# WKUP_CTRL_MMR_WKUP_CTRL_MMR_CFG0_43000000h register map
Vendor: Texas Instruments
Registers are 32-bit, read-write, reset 0x0 unless marked. A register's access mark holds for its fields unless they carry their own. Offsets are as the file gives them; [hi:lo] are bit positions; {n}, {i} and the like mark numbered series.

## WKUP_CTRL_MMR_CFG0 (part 2 of 3)
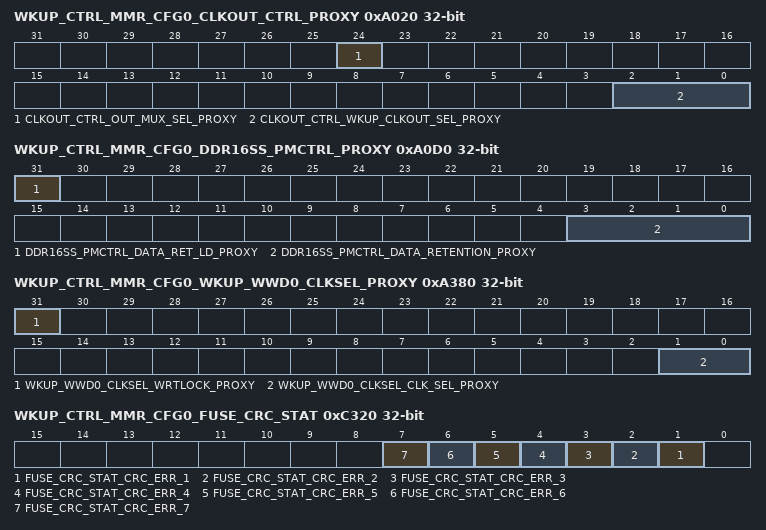
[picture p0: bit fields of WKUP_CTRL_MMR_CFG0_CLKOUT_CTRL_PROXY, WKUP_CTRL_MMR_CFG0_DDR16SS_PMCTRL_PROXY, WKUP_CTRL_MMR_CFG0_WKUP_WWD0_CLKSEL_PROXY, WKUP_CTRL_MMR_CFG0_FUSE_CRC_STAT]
0xA020 WKUP_CTRL_MMR_CFG0_CLKOUT_CTRL_PROXY
  [24] CLKOUT_CTRL_OUT_MUX_SEL_PROXY — WKUP CLKOUT (Pin) pin output mux selection. HFOSC0_CLK is a direct output from the HFOSC0 Reset Source: mod_por_rst_n
  [2:0] CLKOUT_CTRL_WKUP_CLKOUT_SEL_PROXY — Controls WKUP CLKOUT MUX for WKUP_CLKOUT0 PinField values (others are reserved):undefined - undefined3'b000 - DRIVE_LOWundefined - undefined3'b001 - LFOSC0_CLKOUT3'b010 - MAIN_PLL0_HSDIV2_CLKOUT3'b011 - MAIN_PLL1_HSDIV2_CLKOUT3'b100 - MAIN_PLL2_HSDIV9_CLKOUT3'b101 - DEVICE_CLKOUT_32K3'b110 - CLK_12M_RC3'b111 - HFOSC0_CLKOUT Reset Source: mod_por_rst_n
0xA030 WKUP_CTRL_MMR_CFG0_WKUP_GTC_CLKSEL_PROXY reset 0x1
  [2:0] WKUP_GTC_CLKSEL_CLK_SEL_PROXY — Selects the GTC timebase clock sourceField values (others are reserved):3'b000 - MAIN_PLL2_HSDIV5_CLKOUT3'b001 - MAIN_PLL0_HSDIV6_CLKOUT3'b010 - CPSW2G_CPTS_RFT_CLK3'b011 - Reserved '0'3'b100 - MCU_EXT_REFCLK03'b101 - EXT_REFCLK13'b110 - MCU_SYSCLK0undefined - undefined3'b111 - MAIN_SYSCLK0 Reset Source: mod_g_rst_n
0xA03C WKUP_CTRL_MMR_CFG0_EFUSE_CLKSEL_PROXY
  [0] EFUSE_CLKSEL_CLK_SEL_PROXY — Selects the clock sourceField values (others are reserved):1'b0 - HFOSC0_CLKOUT1'b1 - MAIN_SYSCLK0/16 Reset Source: mod_por_rst_n
0xA0D0 WKUP_CTRL_MMR_CFG0_DDR16SS_PMCTRL_PROXY
  [31] DDR16SS_PMCTRL_DATA_RET_LD_PROXY — Controls latching of the retention valueField values (others are reserved):1'b0 - Latch Closed1'b1 - Latch Open Reset Source: mcu_chip1_rst_n
  [3:0] DDR16SS_PMCTRL_DATA_RETENTION_PROXY — DDR16SS Retention: This is a fault tolerant bit field 0x06 Asserts DDRSS 'data_retention' which will Hi-Z most of the phy output pins except for CKE/RESET# All others (Default 0) : data_retention is deasserted for normal DDR16SS OperationField values (others are reserved):4'b0110 - Retention Activated4'b0000 - Retention Deactivated Reset Source: mcu_chip1_rst_n
0xA190 WKUP_CTRL_MMR_CFG0_USB0_CLKSEL_PROXY
  [0] USB0_CLKSEL_REFCLK_SEL_PROXY — Selects the clock source for the USB0 ref_clk. Field values (others are reserved):1'b0 - HFOSC0_CLKOUT1'b1 - MAIN_PLL0_HSDIV8_CLKOUT Reset Source: mod_g_rst_n
0xA194 WKUP_CTRL_MMR_CFG0_USB1_CLKSEL_PROXY
  [0] USB1_CLKSEL_REFCLK_SEL_PROXY — Selects the clock source for the USB1 ref_clk. Field values (others are reserved):1'b0 - HFOSC0_CLKOUT1'b1 - MAIN_PLL0_HSDIV8_CLKOUT Reset Source: mod_g_rst_n
0xA1B0 WKUP_CTRL_MMR_CFG0_WKUP_TIMER0_CLKSEL_PROXY
  [2:0] WKUP_TIMER0_CLKSEL_CLK_SEL_PROXY — Timer functional clock input select mux controlField values (others are reserved):3'b000 - HFOSC0_CLKOUT3'b001 - DM_CLK/2undefined - undefined3'b010 - CLK_12M_RC3'b011 - MCU_PLL0_HSDIV3_CLKOUT3'b100 - MCU_EXT_REFCLK0 (pin)3'b101 - DEVICE_CLKOUT_32K3'b110 - CPSW2G_CPTS_RFT_CLK3'b111 - CLK_32K_RC Reset Source: sys_por_rst_n
0xA1B4 WKUP_CTRL_MMR_CFG0_WKUP_TIMER1_CLKSEL_PROXY
  [2:0] WKUP_TIMER1_CLKSEL_CLK_SEL_PROXY — Timer functional clock input select mux controlField values (others are reserved):3'b000 - HFOSC0_CLKOUT3'b001 - DM_CLK/2undefined - undefined3'b010 - CLK_12M_RC3'b011 - MCU_PLL0_HSDIV3_CLKOUT3'b100 - MCU_EXT_REFCLK0 (pin)3'b101 - DEVICE_CLKOUT_32K3'b110 - CPSW2G_CPTS_RFT_CLK3'b111 - CLK_32K_RC Reset Source: sys_por_rst_n
0xA340 WKUP_CTRL_MMR_CFG0_WKUP_WWD0_CTRL_PROXY
  [3:0] WKUP_WWD0_CTRL_WWD_STOP_PROXY — Controls Clocks to the WWD Watchdog CounterField values (others are reserved):4'b0000 - WWD Counter Running4'b1010 - WWD Counter Stopped Reset Source: mod_g_rst_n
0xA380 WKUP_CTRL_MMR_CFG0_WKUP_WWD0_CLKSEL_PROXY
  [31] WKUP_WWD0_CLKSEL_WRTLOCK_PROXY — When set, locks WWD0_CLKSEL from further writes until the next module reset. Reset Source: mod_g_rst_n
  [1:0] WKUP_WWD0_CLKSEL_CLK_SEL_PROXY — Windowed watchdog timer functional clock input select mux controlField values (others are reserved):2'b00 - HFOSC0_CLKOUT2'b01 - DEVICE_CLKOUT_32K2'b10 - CLK_12M_RC2'b11 - CLK_32K Reset Source: mod_g_rst_n
0xA600 WKUP_CTRL_MMR_CFG0_WKUP_RTC_CLKSEL_PROXY
  [0] WKUP_RTC_CLKSEL_CLK_SEL_PROXY — Selects the source of the RTC functional clockField values (others are reserved):1'b0 - DEVICE_CLKOUT_32K1'b1 - CLK_32K_RC Reset Source: mod_por_rst_n
{0xB100+4i} WKUP_CTRL_MMR_CFG0_CLAIMREG_P2_R{i} (i=0..12)
  [31:0] CLAIMREG_P2_R{i} — Claim bits for Partition 2 Reset Source: mod_g_rst_n
0xC320 WKUP_CTRL_MMR_CFG0_FUSE_CRC_STAT ro
  [n] FUSE_CRC_STAT_CRC_ERR_{n} (n=1..7) — Indicates eFuse CRC error on chain {n} Reset Source: mod_por_rst_n
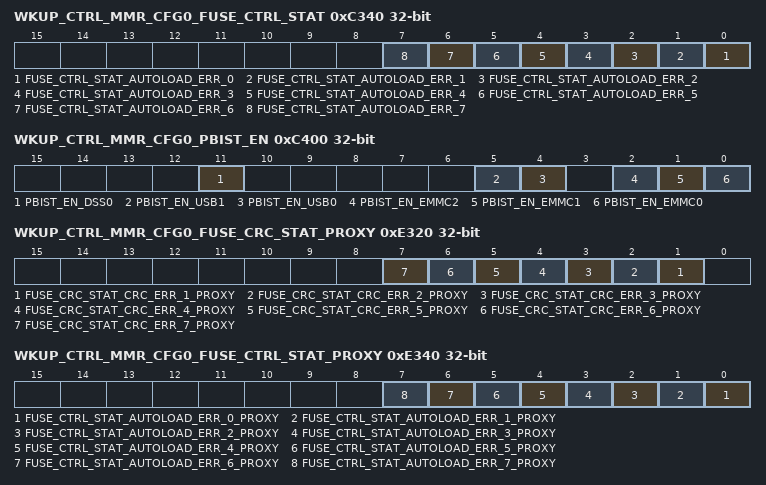
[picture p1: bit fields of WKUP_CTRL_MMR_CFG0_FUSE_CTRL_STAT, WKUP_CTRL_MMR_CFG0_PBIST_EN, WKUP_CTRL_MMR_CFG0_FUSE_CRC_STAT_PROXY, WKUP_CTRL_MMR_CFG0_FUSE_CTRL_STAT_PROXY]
0xC340 WKUP_CTRL_MMR_CFG0_FUSE_CTRL_STAT ro
  [n] FUSE_CTRL_STAT_AUTOLOAD_ERR_{n} (n=0..7) — Autoload Error Status Chain {n} Reset Source: mod_por_rst_n
0xC400 WKUP_CTRL_MMR_CFG0_PBIST_EN
  [11] PBIST_EN_DSS0 — Activates PBIST Access to DSS0 Memories Reset Source: mod_g_rst_n
  [5] PBIST_EN_USB1 — Activates PBIST Access to USB1 Memories Reset Source: mod_g_rst_n
  [4] PBIST_EN_USB0 — Activates PBIST Access to USB0 Memories Reset Source: mod_g_rst_n
  [2] PBIST_EN_EMMC2 — Activates PBIST Access to MMC2 Memories Reset Source: mod_g_rst_n
  [1] PBIST_EN_EMMC1 — Activates PBIST Access to MMC1 Memories Reset Source: mod_g_rst_n
  [0] PBIST_EN_EMMC0 — Activates PBIST Access to MMC0 Memories Reset Source: mod_g_rst_n
{0xD100+4i} WKUP_CTRL_MMR_CFG0_CLAIMREG_P3_R{i}_READONLY ro (i=0..8)
  [31:0] CLAIMREG_P3_R{i}_READONLY — Claim bits for Partition 3 Reset Source: mod_g_rst_n
0xE320 WKUP_CTRL_MMR_CFG0_FUSE_CRC_STAT_PROXY ro
  [n] FUSE_CRC_STAT_CRC_ERR_{n}_PROXY (n=1..7) — Indicates eFuse CRC error on chain {n} Reset Source: mod_por_rst_n
0xE340 WKUP_CTRL_MMR_CFG0_FUSE_CTRL_STAT_PROXY ro
  [n] FUSE_CTRL_STAT_AUTOLOAD_ERR_{n}_PROXY (n=0..7) — Autoload Error Status Chain {n} Reset Source: mod_por_rst_n
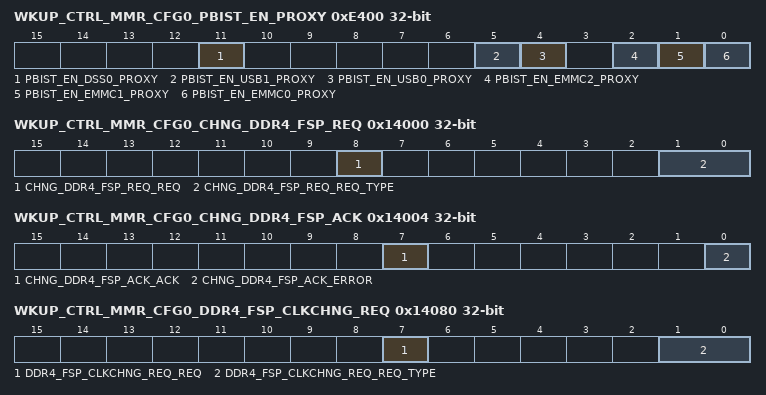
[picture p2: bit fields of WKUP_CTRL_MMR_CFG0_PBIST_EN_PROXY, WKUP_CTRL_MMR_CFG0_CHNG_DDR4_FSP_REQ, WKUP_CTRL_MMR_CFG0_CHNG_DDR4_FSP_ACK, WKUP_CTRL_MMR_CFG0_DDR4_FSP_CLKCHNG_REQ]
0xE400 WKUP_CTRL_MMR_CFG0_PBIST_EN_PROXY
  [11] PBIST_EN_DSS0_PROXY — Activates PBIST Access to DSS0 Memories Reset Source: mod_g_rst_n
  [5] PBIST_EN_USB1_PROXY — Activates PBIST Access to USB1 Memories Reset Source: mod_g_rst_n
  [4] PBIST_EN_USB0_PROXY — Activates PBIST Access to USB0 Memories Reset Source: mod_g_rst_n
  [2] PBIST_EN_EMMC2_PROXY — Activates PBIST Access to MMC2 Memories Reset Source: mod_g_rst_n
  [1] PBIST_EN_EMMC1_PROXY — Activates PBIST Access to MMC1 Memories Reset Source: mod_g_rst_n
  [0] PBIST_EN_EMMC0_PROXY — Activates PBIST Access to MMC0 Memories Reset Source: mod_g_rst_n
{0xF100+4i} WKUP_CTRL_MMR_CFG0_CLAIMREG_P3_R{i} (i=0..8)
  [31:0] CLAIMREG_P3_R{i} — Claim bits for Partition 3 Reset Source: mod_g_rst_n
{0x11100+4i} WKUP_CTRL_MMR_CFG0_CLAIMREG_P4_R{i}_READONLY ro (i=0..8)
  [31:0] CLAIMREG_P4_R{i}_READONLY — Claim bits for Partition 4 Reset Source: mod_g_rst_n
{0x13100+4i} WKUP_CTRL_MMR_CFG0_CLAIMREG_P4_R{i} (i=0..8)
  [31:0] CLAIMREG_P4_R{i} — Claim bits for Partition 4 Reset Source: mod_g_rst_n
0x14000 WKUP_CTRL_MMR_CFG0_CHNG_DDR4_FSP_REQ
  [8] CHNG_DDR4_FSP_REQ_REQ — Initiate FSP frequency change Reset Source: mod_por_rst_n
  [1:0] CHNG_DDR4_FSP_REQ_REQ_TYPE — Frequency request typeIndicates which DDR4 frequency set point to change to Reset Source: mod_por_rst_n
0x14004 WKUP_CTRL_MMR_CFG0_CHNG_DDR4_FSP_ACK ro
  [7] CHNG_DDR4_FSP_ACK_ACK — Frequency change acknowledge.This bit is only valid when CHNG_DDR4_FSP_REQ_req = 1Indication from the DDR Controller that the FSP change operation is complete 0 - FSP change operation in progress 1 - FSP change operation complete Reset Source: mod_por_rst_n
  [0] CHNG_DDR4_FSP_ACK_ERROR — Frequency change errorThis bit is only valid when CHNG_DDR4_FSP_REQ_req = 1 0 - FSP change was sucessful 1 - FSP change was not sucessful Reset Source: mod_por_rst_n
0x14080 WKUP_CTRL_MMR_CFG0_DDR4_FSP_CLKCHNG_REQ ro
  [7] DDR4_FSP_CLKCHNG_REQ_REQ — DDR Controller FSP clock change requestIndicates that the DDR controller needs the DDR clock changed to the frequency indicated by the req_type field. This bit is cleared when the DDR4_FSP_CLKCHNG_ACK_ack bit is set. Reset Source: mod_por_rst_n
  [1:0] DDR4_FSP_CLKCHNG_REQ_REQ_TYPE — Frequency request typeIndicates which DDR4 FSP frequency to which the DDR Controller wants the DDR clock set Reset Source: mod_por_rst_n
0x140C0 WKUP_CTRL_MMR_CFG0_DDR4_FSP_CLKCHNG_ACK
  [0] DDR4_FSP_CLKCHNG_ACK_ACK — DDR FSP clock change ackowledgeThis bit should be set once the DDR clock has been sucessfully changed to the value requested by DDR4_FSP_CLKCHNG_REQ_req_type. Setting this bit will clear the DDR4_FSP_CLKCHNG_REQ_req bit and the associated change request interrupt. Reset Source: mod_por_rst_n
0x15100 WKUP_CTRL_MMR_CFG0_CLAIMREG_P5_R0_READONLY ro
  [31:0] CLAIMREG_P5_R0_READONLY — Claim bits for Partition 5 Reset Source: mod_g_rst_n
0x15104 WKUP_CTRL_MMR_CFG0_CLAIMREG_P5_R1_READONLY ro
  [31:0] CLAIMREG_P5_R1_READONLY — Claim bits for Partition 5 Reset Source: mod_g_rst_n
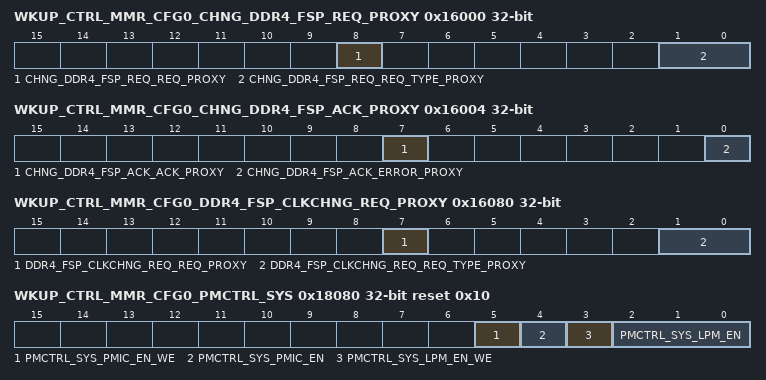
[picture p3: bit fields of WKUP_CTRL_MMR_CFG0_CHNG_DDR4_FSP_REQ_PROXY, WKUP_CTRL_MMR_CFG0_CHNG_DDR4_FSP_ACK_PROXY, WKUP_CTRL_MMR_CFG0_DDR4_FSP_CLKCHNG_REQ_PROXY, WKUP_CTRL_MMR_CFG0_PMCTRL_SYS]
0x16000 WKUP_CTRL_MMR_CFG0_CHNG_DDR4_FSP_REQ_PROXY
  [8] CHNG_DDR4_FSP_REQ_REQ_PROXY — Initiate FSP frequency change Reset Source: mod_por_rst_n
  [1:0] CHNG_DDR4_FSP_REQ_REQ_TYPE_PROXY — Frequency request typeIndicates which DDR4 frequency set point to change to Reset Source: mod_por_rst_n
0x16004 WKUP_CTRL_MMR_CFG0_CHNG_DDR4_FSP_ACK_PROXY ro
  [7] CHNG_DDR4_FSP_ACK_ACK_PROXY — Frequency change acknowledge.This bit is only valid when CHNG_DDR4_FSP_REQ_req = 1Indication from the DDR Controller that the FSP change operation is complete 0 - FSP change operation in progress 1 - FSP change operation complete Reset Source: mod_por_rst_n
  [0] CHNG_DDR4_FSP_ACK_ERROR_PROXY — Frequency change errorThis bit is only valid when CHNG_DDR4_FSP_REQ_req = 1 0 - FSP change was sucessful 1 - FSP change was not sucessful Reset Source: mod_por_rst_n
0x16080 WKUP_CTRL_MMR_CFG0_DDR4_FSP_CLKCHNG_REQ_PROXY ro
  [7] DDR4_FSP_CLKCHNG_REQ_REQ_PROXY — DDR Controller FSP clock change requestIndicates that the DDR controller needs the DDR clock changed to the frequency indicated by the req_type field. This bit is cleared when the DDR4_FSP_CLKCHNG_ACK_ack bit is set. Reset Source: mod_por_rst_n
  [1:0] DDR4_FSP_CLKCHNG_REQ_REQ_TYPE_PROXY — Frequency request typeIndicates which DDR4 FSP frequency to which the DDR Controller wants the DDR clock set Reset Source: mod_por_rst_n
0x160C0 WKUP_CTRL_MMR_CFG0_DDR4_FSP_CLKCHNG_ACK_PROXY
  [0] DDR4_FSP_CLKCHNG_ACK_ACK_PROXY — DDR FSP clock change ackowledgeThis bit should be set once the DDR clock has been sucessfully changed to the value requested by DDR4_FSP_CLKCHNG_REQ_req_type. Setting this bit will clear the DDR4_FSP_CLKCHNG_REQ_req bit and the associated change request interrupt. Reset Source: mod_por_rst_n
0x17100 WKUP_CTRL_MMR_CFG0_CLAIMREG_P5_R0
  [31:0] CLAIMREG_P5_R0 — Claim bits for Partition 5 Reset Source: mod_g_rst_n
0x17104 WKUP_CTRL_MMR_CFG0_CLAIMREG_P5_R1
  [31:0] CLAIMREG_P5_R1 — Claim bits for Partition 5 Reset Source: mod_g_rst_n
0x18040 WKUP_CTRL_MMR_CFG0_FW_CTRL_OUT0
  [31:0] FW_CTRL_OUT0_FW_CTRL_OUT0 — Reset Source: mod_g_rst_n
0x18044 WKUP_CTRL_MMR_CFG0_FW_CTRL_OUT0_SET access not given
  [31:0] FW_CTRL_OUT0_SET_FW_CTRL_OUT0 — reserved Reset Source: mod_g_rst_n (access R/W1TS)
0x18048 WKUP_CTRL_MMR_CFG0_FW_CTRL_OUT0_CLR access not given
  [31:0] FW_CTRL_OUT0_CLR_FW_CTRL_OUT0 — reserved Reset Source: mod_g_rst_n (access R/W1TC)
0x1804C WKUP_CTRL_MMR_CFG0_FW_STS_IN0 ro
  [31:0] FW_STS_IN0_EVENT — Reserved Reset Source: mod_g_rst_n
0x18050 WKUP_CTRL_MMR_CFG0_FW_CTRL_OUT1
  [31:0] FW_CTRL_OUT1_FW_CTRL_OUT1 — reserved Reset Source: mod_g_rst_n
0x18054 WKUP_CTRL_MMR_CFG0_FW_CTRL_OUT1_SET access not given
  [31:0] FW_CTRL_OUT1_SET_FW_CTRL_OUT1 — reserved Reset Source: mod_g_rst_n (access R/W1TS)
0x18058 WKUP_CTRL_MMR_CFG0_FW_CTRL_OUT1_CLR access not given
  [31:0] FW_CTRL_OUT1_CLR_FW_CTRL_OUT1 — reserved Reset Source: mod_g_rst_n (access R/W1TC)
0x1805C WKUP_CTRL_MMR_CFG0_FW_STS_IN1 ro
  [31:0] FW_STS_IN1_EVENT — Reserved Reset Source: mod_g_rst_n
0x18080 WKUP_CTRL_MMR_CFG0_PMCTRL_SYS reset 0x10
  [5] PMCTRL_SYS_PMIC_EN_WE — Unused Field - Value is Don't Care Reset Source: mod_g_rst_n
  [4] PMCTRL_SYS_PMIC_EN — Controls state of PMIC_LPM_EN_OUT when LPM_EN[2:0] is 000 Reset Source: mod_g_rst_n
  [3] PMCTRL_SYS_LPM_EN_WE — Unused Field - Value is Don't Care Reset Source: mod_g_rst_n
  [2:0] PMCTRL_SYS_LPM_EN — Controls whether PMIC_LPM_EN_OUT is driven by the pmic_en bit, or by deep sleep logic. Field values (others are reserved):3'b000 - PMIC_LPM_EN_OUT controlled by pmic_en bit.3'b101 - PMIC_LPM_EN_OUT controlled by DeepSleep Logic Reset Source: mod_g_rst_n
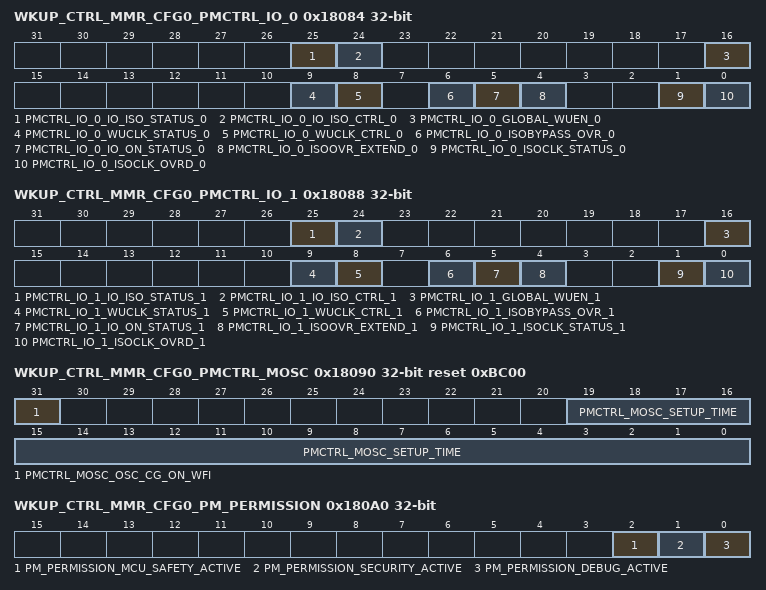
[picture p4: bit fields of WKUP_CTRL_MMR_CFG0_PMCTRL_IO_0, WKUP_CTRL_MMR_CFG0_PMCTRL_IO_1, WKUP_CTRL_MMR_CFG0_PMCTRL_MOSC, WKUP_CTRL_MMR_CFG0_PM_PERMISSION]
0x18084 WKUP_CTRL_MMR_CFG0_PMCTRL_IO_0 access per field
  [25] PMCTRL_IO_0_IO_ISO_STATUS_0 ro — IO ISO Status. Read 0: IO isolation not active. Read 1: IO isolation active.Reflects value of DM input port io_isoack coming back fromIO pad ring. Reset Source: mod_g_rst_n
  [24] PMCTRL_IO_0_IO_ISO_CTRL_0 rw — IO ISO control. Writing this bit to 1 will kick off IO isolation. Reset Source: mod_g_rst_n
  [16] PMCTRL_IO_0_GLOBAL_WUEN_0 rw — Global IO wakeup activate. This is a gating condition to allindividual IO WUEN coming from control module. Gating isdone in the Spinner logic. 0:All individual IO WUEN are gatedin the Spinner logic (override to 0). 1: All individual IO WUENfrom control module are going to Ios.Map to DM input port io_globalwkupen Reset Source: mod_g_rst_n
  [9] PMCTRL_IO_0_WUCLK_STATUS_0 ro — Reflects value of DM input port io_wuclkack coming backfrom IO pad ring. Reset Source: mod_g_rst_n
  [8] PMCTRL_IO_0_WUCLK_CTRL_0 rw — Direct control on WUCLKIN signal to IO pad ring.0:WUCLKINsignal is driven to 0.IO wakeup daisy chain is functional as wellas IO whose wakeup feature is activated. 1:WUCLKIN signal is driven to 1. IO wakeup daisy chain is reset and is latching current pad states and WUEN inputs. Reset Source: mod_g_rst_n
  [6] PMCTRL_IO_0_ISOBYPASS_OVR_0 rw — This MMR bit drives directly DM output port io_isobypassundefined. Reset Source: mod_g_rst_n
  [5] PMCTRL_IO_0_IO_ON_STATUS_0 ro — Gives the functional status of the IO ring. Read 0: Part or all ofthe Ios are not in the ON state that is are in isolation state.Read 1: All Ios are in the ON state.io_on_status = assign 1 if (io_iso == 0 & io_isoack==0 &io_iso_clk == 0 & io_isoclk_ack = 0 ) else 0; Reset Source: mod_g_rst_n
  [4] PMCTRL_IO_0_ISOOVR_EXTEND_0 rw — This drives the SOC chain ISO-OVERRIDE global control.This bit drives directly the DM output port io_isoovrundefined. Atthe SOC level it is used to activate when 1 or gate-off when 0,the individual ISOOR for each IO. This operates as a globalactivate/deactivate for the individual IOs.Control for IO isolation extension.'0' IO isolation is not extended. Transition happens as soon asautomatic restore is completed.'1' IO isolation is extended. The IOs whose ISOOVR bits havebeen individually set in their PADCFG MMRs will all get its IOisolation extended beyond the point when the initial IO daisychain isolation is released. Reset Source: mod_g_rst_n
  [1] PMCTRL_IO_0_ISOCLK_STATUS_0 ro — Reflects value of DM input port io_isoclkack coming backfrom IO pad ring. Reset Source: mod_g_rst_n
  [0] PMCTRL_IO_0_ISOCLK_OVRD_0 rw — Override control on ISOCLKIN signal to IO pad ring.When not overridden this signal is controlled by hardware only.0 ISOCLKIN signal is not override.1 ISOCLKIN signal is overridden to active value ('1'). Reset Source: mod_g_rst_n
0x18088 WKUP_CTRL_MMR_CFG0_PMCTRL_IO_1 access per field
  [25] PMCTRL_IO_1_IO_ISO_STATUS_1 ro — IO ISO Status. Read 0: IO isolation not active. Read 1: IO isolation active.Reflects value of DM input port io_isoack coming back fromIO pad ring. Reset Source: mod_g_rst_n
  [24] PMCTRL_IO_1_IO_ISO_CTRL_1 rw — IO ISO control. Writing this bit to 1 will kick off IO isolation. Reset Source: mod_g_rst_n
  [16] PMCTRL_IO_1_GLOBAL_WUEN_1 rw — Global IO wakeup activate. This is a gating condition to allindividual IO WUEN coming from control module. Gating isdone in the Spinner logic. 0:All individual IO WUEN are gatedin the Spinner logic (override to 0). 1: All individual IO WUENfrom control module are going to Ios.Map to DM input port io_globalwkupen Reset Source: mod_g_rst_n
  [9] PMCTRL_IO_1_WUCLK_STATUS_1 ro — Reflects value of DM input port io_wuclkack coming backfrom IO pad ring. Reset Source: mod_g_rst_n
  [8] PMCTRL_IO_1_WUCLK_CTRL_1 rw — Direct control on WUCLKIN signal to IO pad ring.0:WUCLKINsignal is driven to 0.IO wakeup daisy chain is functional as wellas IO whose wakeup feature is activated. 1:WUCLKIN signal is driven to 1. IO wakeup daisy chain is reset and is latching current pad states and WUEN inputs. Reset Source: mod_g_rst_n
  [6] PMCTRL_IO_1_ISOBYPASS_OVR_1 rw — This MMR bit drives directly DM output port io_isobypassundefined. Reset Source: mod_g_rst_n
  [5] PMCTRL_IO_1_IO_ON_STATUS_1 ro — Gives the functional status of the IO ring. Read 0: Part or all ofthe Ios are not in the ON state that is are in isolation state.Read 1: All Ios are in the ON state.io_on_status = assign 1 if (io_iso == 0 & io_isoack==0 &io_iso_clk == 0 & io_isoclk_ack = 0 ) else 0; Reset Source: mod_g_rst_n
  [4] PMCTRL_IO_1_ISOOVR_EXTEND_1 rw — This drives the SOC chain ISO-OVERRIDE global control.This bit drives directly the DM output port io_isoovrundefined. Atthe SOC level it is used to activate when 1 or gate-off when 0,the individual ISOOR for each IO. This operates as a globalactivate/deactivate for the individual IOs.Control for IO isolation extension.'0' IO isolation is not extended. Transition happens as soon asautomatic restore is completed.'1' IO isolation is extended. The IOs whose ISOOVR bits havebeen individually set in their PADCFG MMRs will all get its IOisolation extended beyond the point when the initial IO daisychain isolation is released. Reset Source: mod_g_rst_n
  [1] PMCTRL_IO_1_ISOCLK_STATUS_1 ro — Reflects value of DM input port io_isoclkack coming backfrom IO pad ring. Reset Source: mod_g_rst_n
  [0] PMCTRL_IO_1_ISOCLK_OVRD_1 rw — Override control on ISOCLKIN signal to IO pad ring.When not overridden this signal is controlled by hardware only.0 ISOCLKIN signal is not override.1 ISOCLKIN signal is overridden to active value ('1'). Reset Source: mod_g_rst_n
0x18090 WKUP_CTRL_MMR_CFG0_PMCTRL_MOSC reset 0xBC00
  [31] PMCTRL_MOSC_OSC_CG_ON_WFI — When set by Device Manager - the soc clock gating logic will gate the device manager clock once Device Manager has entered the WFI state. (Note: this was named osc_cg_dis but name didn't match function) Reset Source: mod_g_rst_n
  [19:0] PMCTRL_MOSC_SETUP_TIME — Keep the main oscillator clock gates for the number ofHFOSC clock cycles This is the time it takes to stabilizethe clock source supplier (i.e. Main Oscillator) Reset Source: mod_g_rst_n
0x18098 WKUP_CTRL_MMR_CFG0_PM_MISC_STATUS ro
  [1:0] PM_MISC_STATUS_OSC_CG_STAT — Reflects the status of the request to clock-gate HFoscillator via MMR PMCTRL_MOSCundefined.11: osc_cgen_req = '0' &osc_cgen_ack = '1'10: osc_cgen_req = '1' &osc_cgen_ack = '0'01: osc_cgen_req = '0' &osc_cgen_ack = '0'00: osc_cgen_req = '1' &osc_cgen_ack = '1' Reset Source: mod_g_rst_n
0x1809C WKUP_CTRL_MMR_CFG0_PMCTRL_IO_GLB
  [1:0] PMCTRL_IO_GLB_DSEN_QUALIFIED — To dsen_qualified signal generation logic for daisychain[1:0] logic. Used to control I/O buffer ouput and output activate during deepsleep mode. See IO Integration spec for detail. Reset Source: mod_g_rst_n
0x180A0 WKUP_CTRL_MMR_CFG0_PM_PERMISSION ro
  [2] PM_PERMISSION_MCU_SAFETY_ACTIVE — Read Only - Reads return a 1 when am62_mcu_ctrl_mmr.wkup_0.RST_MAGIC_WORD_mcu_magic_word_ipcfg[31:0] != 32'h0.When 1, indicates that the MCU is blocking reset and also deep sleep entry. Reset Source: mod_g_rst_n
  [1] PM_PERMISSION_SECURITY_ACTIVE — Read Only - Reads return the value of ms.main_0.sms_iopm_pmpermission_security_active. When 1, indicates that SMS is blocking deep sleep entry. Reset Source: mod_g_rst_n
  [0] PM_PERMISSION_DEBUG_ACTIVE — Read Only - Returns a 1 when IceMelter is blocking deep sleep entry. Reset Source: mod_g_rst_n
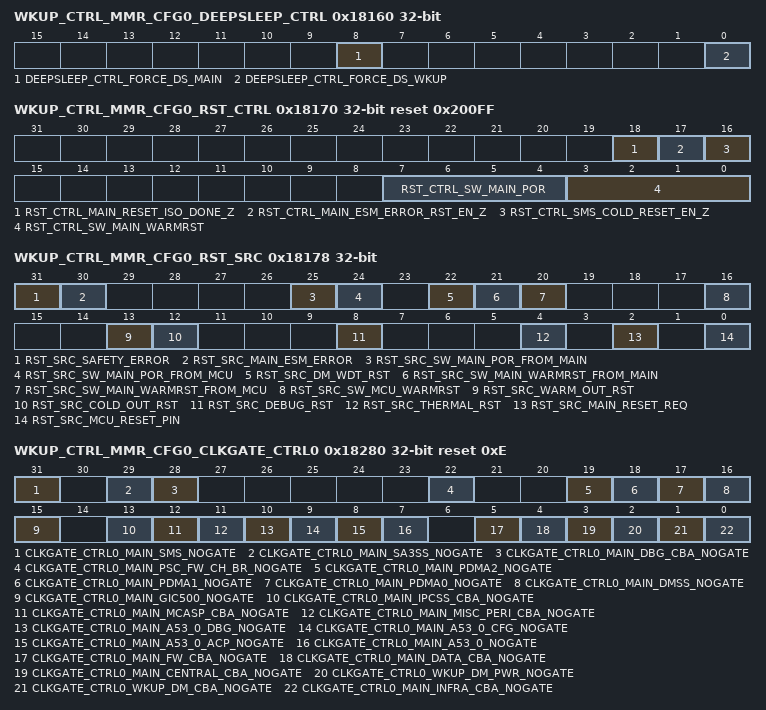
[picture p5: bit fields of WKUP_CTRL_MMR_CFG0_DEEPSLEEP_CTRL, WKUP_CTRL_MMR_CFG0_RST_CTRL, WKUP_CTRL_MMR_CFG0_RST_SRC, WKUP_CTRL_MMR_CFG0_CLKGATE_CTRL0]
0x18160 WKUP_CTRL_MMR_CFG0_DEEPSLEEP_CTRL
  [8] DEEPSLEEP_CTRL_FORCE_DS_MAIN — Force all MAIN IOs into deepsleep mode when set Reset Source: mod_por_rst_n
  [0] DEEPSLEEP_CTRL_FORCE_DS_WKUP — Force all WKUP IOs into deepsleep mode when set Reset Source: mod_por_rst_n
0x18170 WKUP_CTRL_MMR_CFG0_RST_CTRL reset 0x200FF
  [18] RST_CTRL_MAIN_RESET_ISO_DONE_Z — Main Domain CPUs can set this bit to block warm reset in the main domain which is useful when the Main domain may be accessing main domain resources (peripherals, memory..). In this case, the main domain cpus will be notified via an interrupt that there is an outstanding warm reset request for the main domain. Once notified, Main needs to finish any outstanding operations in has with main domain resources and then clear this bit. After this bit is cleared, the main domain warm reset will unblocked and the warm reset sequence may continue. 0 - Reset of Main Domain is not Blocked by Main Domain 1 - Reset of Main Domain is Blocked by Main Domain Reset Source: main_chip1_rst_n
  [17] RST_CTRL_MAIN_ESM_ERROR_RST_EN_Z — Deactivate Reset of Main by ESM 0 - Activated 1 - Deactivated Reset Source: main_chip1_rst_n
  [16] RST_CTRL_SMS_COLD_RESET_EN_Z — Deactivate Reset of Main by SMS 0 - Activated 1 - Deactivated Reset Source: main_chip1_rst_n
  [7:4] RST_CTRL_SW_MAIN_POR — Causes Main Domain Power On Reset when set to 4'b0110, Bits will reset to 4'b1111 Reset Source: main_chip1_rst_n
  [3:0] RST_CTRL_SW_MAIN_WARMRST — Causes Main Domain Warm Reset when set to 4'b0110, Bits will reset to 4'b1111 Reset Source: main_chip1_rst_n
0x18174 WKUP_CTRL_MMR_CFG0_RST_STAT ro
  [0] RST_STAT_MCU_RESET_ISO_DONE_Z — is an outstanding warm reset request for the main domain. Once notified, MCU needs to finish any outstanding Reset Source: main_chip1_rst_n
0x18178 WKUP_CTRL_MMR_CFG0_RST_SRC ro
  [31] RST_SRC_SAFETY_ERROR — Reset Caused by MCU ESM Error Reset Source: main_chip1_rst_n
  [30] RST_SRC_MAIN_ESM_ERROR — Reset Caused by Main ESM Error Reset Source: main_chip1_rst_n
  [25] RST_SRC_SW_MAIN_POR_FROM_MAIN — Software Main Power On Reset From MAIN CTRL MMR Reset Source: main_chip1_rst_n
  [24] RST_SRC_SW_MAIN_POR_FROM_MCU — Software Main Power On Reset From MCU CTRL MMR Reset Source: main_chip1_rst_n
  [22] RST_SRC_DM_WDT_RST — Watchdog Initiated Reset Reset Source: main_chip1_rst_n
  [21] RST_SRC_SW_MAIN_WARMRST_FROM_MAIN — Software Main Warm Reset from MAIN CTRL MMR Reset Source: main_chip1_rst_n
  [20] RST_SRC_SW_MAIN_WARMRST_FROM_MCU — Software Main Warm Reset From MCU CTRL MMR Reset Source: main_chip1_rst_n
  [16] RST_SRC_SW_MCU_WARMRST — Software Warm Reset Reset Source: main_chip1_rst_n
  [13] RST_SRC_WARM_OUT_RST — SMS Warm Reset Reset Source: main_chip1_rst_n
  [12] RST_SRC_COLD_OUT_RST — SMS Cold Reset Reset Source: main_chip1_rst_n
  [8] RST_SRC_DEBUG_RST — Debug Subsystem Initiated Reset Reset Source: main_chip1_rst_n
  [4] RST_SRC_THERMAL_RST — Thermal Reset Reset Source: main_chip1_rst_n
  [2] RST_SRC_MAIN_RESET_REQ — Main Reset Pin Reset Source: main_chip1_rst_n
  [0] RST_SRC_MCU_RESET_PIN — Rest Caused by MCU Reset Pin Reset Source: main_chip1_rst_n
0x1817C WKUP_CTRL_MMR_CFG0_RST_MAGIC_WORD ro
  [31:0] RST_MAGIC_WORD_MCU_MAGIC_WORD — Magic Word Indicating Status of MCU Subsystem Boot Reset Source: main_chip1_rst_n
0x18180 WKUP_CTRL_MMR_CFG0_WKUP0_EN
  [31:0] WKUP0_EN_WKUPEN — Activates Wakeup from: b0 - WKUP I2C0 b1 - WKUP USART0 b2 - MCU GPIO0 b3 - DEBUG (IceMelter) b4 - Reserved b5 - WKUP DMTIMER0 b6 - WKUP DMTIMER1 b7 - WKUP RTC b8 - Main RESET_REQz b9 - USB0 In Band b10 - USB1 In Band b16 - MAIN IO Daisy Chain b17 - MCU IO Daisy Chain b18 - CANUART IO Daisy Chain Reset Source: mod_g_rst_n
0x18280 WKUP_CTRL_MMR_CFG0_CLKGATE_CTRL0 reset 0xE
  [31] CLKGATE_CTRL0_MAIN_SMS_NOGATE — MAIN domain SMS (pwr_dis_nogate) clock gate deactivate. 0 - Clocks are gated on idle for power savings 1 - Clocks are not gated on idle, power saving deactivated Reset Source: mod_por_rst_n
  [29] CLKGATE_CTRL0_MAIN_SA3SS_NOGATE — MAIN domain SA3SS clock gate deactivate. 0 - Clocks are gated on idle for power savings 1 - Clocks are not gated on idle, power saving deactivated Reset Source: mod_por_rst_n
  [28] CLKGATE_CTRL0_MAIN_DBG_CBA_NOGATE — MAIN domain Debug CBA (main_dbg_cba)clock gate deactivate. 0 - Clocks are gated on idle for power savings 1 - Clocks are not gated on idle, power saving deactivated Reset Source: mod_por_rst_n
  [22] CLKGATE_CTRL0_MAIN_PSC_FW_CH_BR_NOGATE — (Non-Functional) MAIN domain (psc_fw_ch_br_nogate) 0 - Clocks are gated on idle for power savings 1 - Clocks are not gated on idle, power saving deactivated Reset Source: mod_por_rst_n
  [19] CLKGATE_CTRL0_MAIN_PDMA2_NOGATE — MAIN domain PDMA2 (pwr_dis_nogate) clock gate deactivate. 0 - Clocks are gated on idle for power savings 1 - Clocks are not gated on idle, power saving deactivated Reset Source: mod_por_rst_n
  [18] CLKGATE_CTRL0_MAIN_PDMA1_NOGATE — MAIN domain PDMA1 (pwr_dis_nogate) clock gate deactivate. 0 - Clocks are gated on idle for power savings 1 - Clocks are not gated on idle, power saving deactivated Reset Source: mod_por_rst_n
  [17] CLKGATE_CTRL0_MAIN_PDMA0_NOGATE — MAIN domain PDMA0 (pwr_dis_nogate) clock gate deactivate. 0 - Clocks are gated on idle for power savings 1 - Clocks are not gated on idle, power saving deactivated Reset Source: mod_por_rst_n
  [16] CLKGATE_CTRL0_MAIN_DMSS_NOGATE — MAIN domain DMSS (pwr_dis_nogate) clock gate deactivate. 0 - Clocks are gated on idle for power savings 1 - Clocks are not gated on idle, power saving deactivated Reset Source: mod_por_rst_n
  [15] CLKGATE_CTRL0_MAIN_GIC500_NOGATE — MAIN A53SS0 (gic500_1_2) clock gate deactivate. 0 - Clocks are gated on idle for power savings 1 - Clocks are not gated on idle, power saving deactivated Reset Source: mod_por_rst_n
  [13] CLKGATE_CTRL0_MAIN_IPCSS_CBA_NOGATE — MAIN domain Infrastructure bus (main_ipcss_cbass) clock gate deactivate. 0 - Clocks are gated on idle for power savings 1 - Clocks are not gated on idle, power saving deactivated Reset Source: mod_por_rst_n
  [12] CLKGATE_CTRL0_MAIN_MCASP_CBA_NOGATE — MAIN domain Infrastructure bus (main_mcasp_cbass) clock gate deactivate. 0 - Clocks are gated on idle for power savings 1 - Clocks are not gated on idle, power saving deactivated Reset Source: mod_por_rst_n
  [11] CLKGATE_CTRL0_MAIN_MISC_PERI_CBA_NOGATE — MAIN domain Infrastructure bus (main_misc_peri_cbass) clock gate deactivate. 0 - Clocks are gated on idle for power savings 1 - Clocks are not gated on idle, power saving deactivated Reset Source: mod_por_rst_n
  [10] CLKGATE_CTRL0_MAIN_A53_0_DBG_NOGATE — MAIN A53SS0 Debug Port clock gate deactivate. 0 - Clocks are gated on idle for power savings 1 - Clocks are not gated on idle, power saving deactivated Reset Source: mod_por_rst_n
  [9] CLKGATE_CTRL0_MAIN_A53_0_CFG_NOGATE — MAIN A53SS0 Configuration Port clock gate deactivate. 0 - Clocks are gated on idle for power savings 1 - Clocks are not gated on idle, power saving deactivated Reset Source: mod_por_rst_n
  [8] CLKGATE_CTRL0_MAIN_A53_0_ACP_NOGATE — MAIN A53SS0 ACP clock gate deactivate. 0 - Clocks are gated on idle for power savings 1 - Clocks are not gated on idle, power saving deactivated Reset Source: mod_por_rst_n
  [7] CLKGATE_CTRL0_MAIN_A53_0_NOGATE — MAIN A53SS0 clock gate deactivate. 0 - Clocks are gated on idle for power savings 1 - Clocks are not gated on idle, power saving deactivated Reset Source: mod_por_rst_n
  [5] CLKGATE_CTRL0_MAIN_FW_CBA_NOGATE — MAIN domain datal bus (main_fw_cbass) clock gate deactivate. 0 - Clocks are gated on idle for power savings 1 - Clocks are not gated on idle, power saving deactivated Reset Source: mod_por_rst_n
  [4] CLKGATE_CTRL0_MAIN_DATA_CBA_NOGATE — MAIN domain data bus (main_cbass) clock gate deactivate. 0 - Clocks are gated on idle for power savings 1 - Clocks are not gated on idle, power saving deactivated Reset Source: mod_por_rst_n
  [3] CLKGATE_CTRL0_MAIN_CENTRAL_CBA_NOGATE — WKUP domain Infrastructure ECC aggregator(wkup_safe_ecc_aggr) clock gate deactivate. 0 - Clocks are gated on idle for power savings 1 - Clocks are not gated on idle, power saving deactivated Reset Source: mod_por_rst_n
  [2] CLKGATE_CTRL0_WKUP_DM_PWR_NOGATE — WKUP domain Device Manager (wkup_dm_pwr_nogate) clock gate deactivate. 0 - Clocks are gated on idle for power savings 1 - Clocks are not gated on idle, power saving deactivated Reset Source: mod_por_rst_n
  [1] CLKGATE_CTRL0_WKUP_DM_CBA_NOGATE — WKUP domain device manager CBA clock gate deactivate. 0 - Clocks are gated on idle for power savings 1 - Clocks are not gated on idle, power saving deactivated Reset Source: mod_por_rst_n
  [0] CLKGATE_CTRL0_MAIN_INFRA_CBA_NOGATE — MAIN domain Infrastructure bus (main_infra_cbass and psc_fw_ch_br) clock gate deactivate. 0 - Clocks are gated on idle for power savings 1 - Clocks are not gated on idle, power saving deactivated Reset Source: mod_por_rst_n
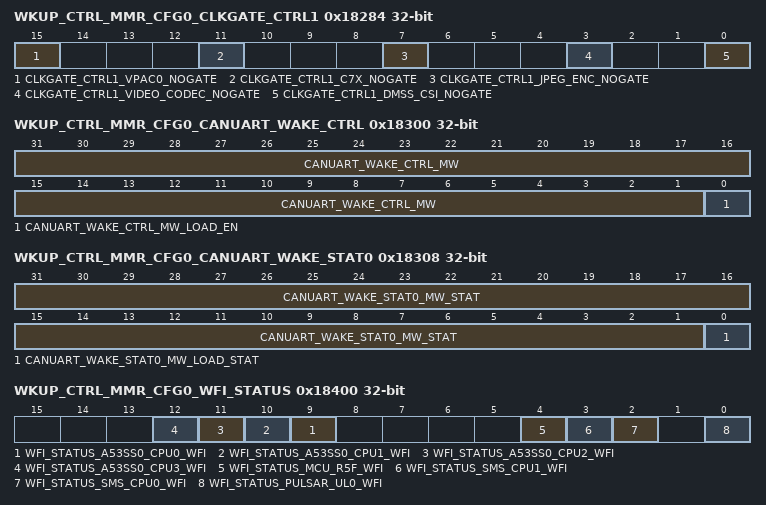
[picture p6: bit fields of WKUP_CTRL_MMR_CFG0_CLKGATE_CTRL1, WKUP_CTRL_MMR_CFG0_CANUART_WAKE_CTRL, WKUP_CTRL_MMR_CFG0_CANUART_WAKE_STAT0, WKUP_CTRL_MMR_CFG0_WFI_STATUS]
0x18284 WKUP_CTRL_MMR_CFG0_CLKGATE_CTRL1
  [15] CLKGATE_CTRL1_VPAC0_NOGATE — VPAC0 clock gate deactivate. 0 - Clocks are gated on idle for power savings 1 - Clocks are not gated on idle, power saving deactivated Reset Source: mod_por_rst_n
  [11] CLKGATE_CTRL1_C7X_NOGATE — C7x clock gate deactivate. 0 - Clocks are gated on idle for power savings 1 - Clocks are not gated on idle, power saving deactivated Reset Source: mod_por_rst_n
  [7] CLKGATE_CTRL1_JPEG_ENC_NOGATE — JPEG Encoder clock gate deactivate. 0 - Clocks are gated on idle for power savings 1 - Clocks are not gated on idle, power saving deactivated Reset Source: mod_por_rst_n
  [3] CLKGATE_CTRL1_VIDEO_CODEC_NOGATE — VIDEO CODEC clock gate deactivate. 0 - Clocks are gated on idle for power savings 1 - Clocks are not gated on idle, power saving deactivated Reset Source: mod_por_rst_n
  [0] CLKGATE_CTRL1_DMSS_CSI_NOGATE — DMSS_CSI clock gate deactivate. 0 - Clocks are gated on idle for power savings 1 - Clocks are not gated on idle, power saving deactivated Reset Source: mod_por_rst_n
0x18300 WKUP_CTRL_MMR_CFG0_CANUART_WAKE_CTRL
  [31:1] CANUART_WAKE_CTRL_MW — CANUART IO magic word. This 31-bit value that activates placing of the CANUART I/Os into isolation for daisy-chain wakeup operation. The Upper 8 bits are software defined. The lower 23 bits are checked by hardware:- 0x5AAAAA - Magic word value to activate isolation whenqualified with mw_load bit- Others - Any other value will prevent isolation when mw_loadtransitions from 0 to 1 Reset Source: mcu_chip1_rst_n
  [0] CANUART_WAKE_CTRL_MW_LOAD_EN — Magic word load activateSetting this bit to 1 loads and locks the mw field for CANUART IO isolation. If the mw field matches the magicword value then the value is latched into the CANUART IOvoltage domain and CANUART IO isolation is activated.0 - Unlock and do not load mw value for comparison1 - Load and lock mw for magic word value comparison Reset Source: mcu_chip1_rst_n
0x18308 WKUP_CTRL_MMR_CFG0_CANUART_WAKE_STAT0 ro
  [31:1] CANUART_WAKE_STAT0_MW_STAT — CANUART magic word statusIndicates the latched value of the mw field. Reset Source: mod_por_rst_n
  [0] CANUART_WAKE_STAT0_MW_LOAD_STAT — Magic word load status.Indicates the latched value of the mw_load_en bit Reset Source: mod_por_rst_n
0x1830C WKUP_CTRL_MMR_CFG0_CANUART_WAKE_STAT1 ro
  [0] CANUART_WAKE_STAT1_CANUART_IO_MODE — Indicates if CANUART IO wakeup mode is activated.0 - Not activated (load_en not set or mw doesn't match magic word)1 - CANUART IO mode activated Reset Source: mod_por_rst_n
0x18310 WKUP_CTRL_MMR_CFG0_CANUART_WAKE_OFF_MODE
  [31:0] CANUART_WAKE_OFF_MODE_MW — magic word Reset Source: mod_por_rst_n
0x18318 WKUP_CTRL_MMR_CFG0_CANUART_WAKE_OFF_MODE_STAT ro
  [31:0] CANUART_WAKE_OFF_MODE_STAT_MW — returned magic word Reset Source: mod_por_rst_n
0x18320 WKUP_CTRL_MMR_CFG0_CANUART_WAKE_RESUME_KEY_j
  [31:0] KEYVAL — key value Reset Source: mod_por_rst_n
0x18340 WKUP_CTRL_MMR_CFG0_CANUART_WAKE_RESUME_KEY_STAT_j ro
  [31:0] KEYVAL — returned key value Reset Source: mod_por_rst_n
0x18400 WKUP_CTRL_MMR_CFG0_WFI_STATUS ro
  [n+9] WFI_STATUS_A53SS0_CPU{n}_WFI (n=0..3) — WFI status of A53SS0 CPU{n} Reset Source: mod_por_rst_n
  [4] WFI_STATUS_MCU_R5F_WFI — WFI status of MCU Cortex R5F Reset Source: mod_por_rst_n
  [3] WFI_STATUS_SMS_CPU1_WFI — WFI status of SMS Cortex M4F1 Reset Source: mod_por_rst_n
  [2] WFI_STATUS_SMS_CPU0_WFI — WFI status of SMS Cortex M4F0 Reset Source: mod_por_rst_n
  [0] WFI_STATUS_PULSAR_UL0_WFI — WFI status of Device Manager Cortex R5F Reset Source: mod_por_rst_n
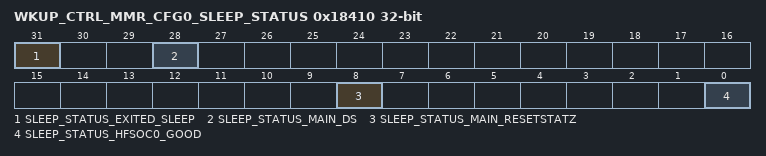
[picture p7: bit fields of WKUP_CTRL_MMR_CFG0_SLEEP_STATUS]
0x18410 WKUP_CTRL_MMR_CFG0_SLEEP_STATUS access not given
  [31] SLEEP_STATUS_EXITED_SLEEP — Set when the HFXOSC clock gate is activated (rising edge capture of OSC_CG_ACK). To be read and cleared by DM after exiting WFI as a status signal distinguishing the case where WFI was entered and the clock was stopped, then exited with a wakeup (this bit will be set) from the case where an interrupt or other event caused the WFI sequence to stop and the HFXOSC was never stopped. Reset Source: sys_por_rst_n (access R/W1TC)
  [28] SLEEP_STATUS_MAIN_DS — Set when the main domain deep sleep power on reset / power domain off is activated. (rising edge detect of am62_wkup_ctrl_mmr.wkup_0.DS_MAIN_por_pdoff_ft_out_ipcfg). This will be checked by the ROM on TIFS upon exiting from reset to determine if it is a power on reset or exiting deep sleep. Reset Source: sys_por_rst_n (access R/W1TC)
  [8] SLEEP_STATUS_MAIN_RESETSTATZ ro — Reflects the status of the main domain resetz signalField values (others are reserved):1'b0 - Main Domain In Reset1'b1 - Main Domain Out of Reset Reset Source: mod_g_rst_n
  [0] SLEEP_STATUS_HFSOC0_GOOD ro — Reserved Reset Source: mod_g_rst_n
0x18418 WKUP_CTRL_MMR_CFG0_DS_MAGIC_WORD
  [31:0] DS_MAGIC_WORD_DS_MAGIC_WORD — Magic Word Indicating State of Deep Sleep Reset Source: main_chip1_rst_n
0x18420 WKUP_CTRL_MMR_CFG0_DS_MAIN reset 0xF
  [3:0] DS_MAIN_POR_PDOFF — Signal Puts main SMS, DebugSS and MainIP Power Domains into Power Off state, and asserts Main Power On Reset.Field values (others are reserved):4'b0110 - Off4'b1111 - On Reset Source: mcu_chip1_rst_n
